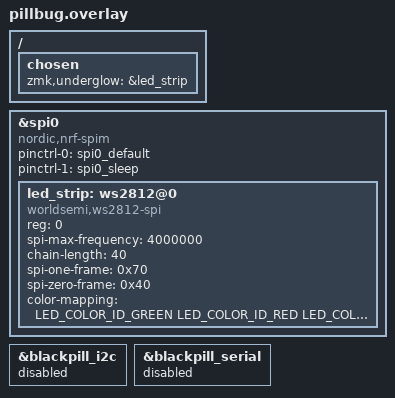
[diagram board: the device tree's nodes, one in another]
#include <dt-bindings/led/led.h>


&spi0 {
  compatible = "nordic,nrf-spim";
  status = "okay";

  pinctrl-0 = <&spi0_default>;
  pinctrl-1 = <&spi0_sleep>;
  pinctrl-names = "default", "sleep";

  led_strip: ws2812@0 {
    compatible = "worldsemi,ws2812-spi";

    /* SPI */
    reg = <0>; /* ignored, but necessary for SPI bindings */
    spi-max-frequency = <4000000>;

    /* WS2812 */
    chain-length = <40>; /* number of LEDs */
    spi-one-frame = <0x70>;
    spi-zero-frame = <0x40>;
    color-mapping = <LED_COLOR_ID_GREEN
                          LED_COLOR_ID_RED
                          LED_COLOR_ID_BLUE>;
  };
};



&blackpill_i2c {
    status = "disabled";
};

&blackpill_serial {
    status = "disabled";
};

/ {
    chosen {
        zmk,underglow = &led_strip;
    };
};


